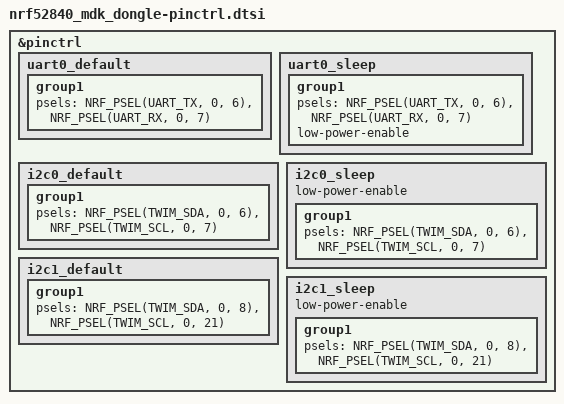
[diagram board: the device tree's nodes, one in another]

&pinctrl {
	uart0_default: uart0_default {
		group1 {
			psels = <NRF_PSEL(UART_TX, 0, 6)>,
				<NRF_PSEL(UART_RX, 0, 7)>;
		};
	};

	uart0_sleep: uart0_sleep {
		group1 {
			psels = <NRF_PSEL(UART_TX, 0, 6)>,
				<NRF_PSEL(UART_RX, 0, 7)>;
			low-power-enable;
		};
	};
	i2c0_default: i2c0_default {
		group1 {
			psels = <NRF_PSEL(TWIM_SDA, 0, 6)>,
				<NRF_PSEL(TWIM_SCL, 0, 7)>;
		};
	};

	i2c0_sleep: i2c0_sleep {
		group1 {
			psels = <NRF_PSEL(TWIM_SDA, 0, 6)>,
				<NRF_PSEL(TWIM_SCL, 0, 7)>;
		};

			low-power-enable;
	};

	i2c1_default: i2c1_default {
		group1 {

			psels = <NRF_PSEL(TWIM_SDA, 0, 8)>,
				<NRF_PSEL(TWIM_SCL, 0, 21)>;
		};
	};

	i2c1_sleep: i2c1_sleep {
		group1 {
			psels = <NRF_PSEL(TWIM_SDA, 0, 8)>,
				<NRF_PSEL(TWIM_SCL, 0, 21)>;
		};

			low-power-enable;
	};

};
